# A31G12x_series register map
Vendor: ABOV Semiconductor Co., Ltd.; Series: A31G12x_series; File version: 1.0
CPU: CM0PLUS r0p1, little endian, no MPU, no FPU, VTOR, 2 interrupt priority bits
Registers are 32-bit, read-write, reset 0x0 unless marked. A register's access mark holds for its fields unless they carry their own. Offsets are from the block's base; [hi:lo] are bit positions; {n}, {i} and the like mark numbered series; 'fields as' and 'values as' point back to an identical list.

## CRC — CYCLIC REDUNDANCY CHECK AND CHECKSUM
Base 0x30001000
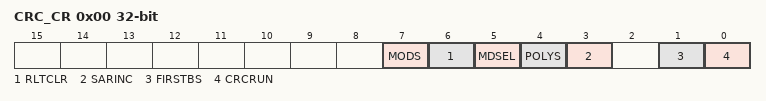
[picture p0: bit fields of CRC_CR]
0x00 CRC_CR — CRC/Checksum Control Register. Notes: 1. The CRCRLT register and the CRC/Checksum block should be initialized by writing "1b" to the RLTCLR bit before a new CRC/Checksum calculation. 2. The CRCRUN bit should be set to "1b" last time after setting appropriate values to the registers. 3. On the user mode, it will be calculated every writing data to the CRCIN register during CRCRUN==1. 4. On the user mode with SARINC==0, the block is finished by writing "0b" to the CRCRUN bit. 4. It is prohibited writing any data to the CRCIN register during CRCRUN==0. 5. The checksum is calculated by byte unit. Ex) On 0x34A7E991, CRCRLT = 0x34 + 0xA7 + 0xE9 + 0x91.
  [7] MODS — User/Auto Mode Selection bit
  [6] RLTCLR — CRC/Checksum Result Data Register (CRCRLT) Initialization bit
  [5] MDSEL — CRC/Checksum Selection bit
  [4] POLYS — Polynomial Selection bit (CRC only)
  [3] SARINC — CRC/Checksum Start Address Auto Increment Control bit (User mode only)
  [1] FIRSTBS — First Shifted-in Selection bit (CRC only)
  [0] CRCRUN — CRC/Checksum Start Control and Busy bit
0x04 CRC_IN — CRC/Checksum Input Data Register
0x08 CRC_RLT ro reset 0xFFFF (reset mask 0xFFFF) — CRC/Checksum Result Data Register
0x0C CRC_INIT (reset mask 0xFFFF) — CRC/Checksum Initial Data Register
0x10 CRC_SADR reset 0x10000000 (reset mask 0xFFFFFFFC) — CRC/Checksum Start Address Register. Note: The LSB-7bits of the start address should be "0x00" on the "Auto mode".
0x14 CRC_EADR reset 0x10007FFC (reset mask 0xFFFFFFFC) — CRC/Checksum End Address Register. Note: The LSB-7bits of the end address should be "0x7c" on the "Auto mode".

## INT — Interrupt
Base 0x40001000
0x04 INTC_PBTRIG (reset mask 0xFFF) — Port B Interrupt Trigger Selection Register
  [n] ITRIG{n} (n=2..11) — Pin {n} Interrupt Trigger Selection bit
  [?] ITRIG1 — Pin 1 Interrupt Trigger Selection bit
  [0] ITRIG0 — Pin 0 Interrupt Trigger Selection bit
0x08 INTC_PCTRIG (reset mask 0xF) — Port C Interrupt Trigger Selection Register
  [n] ITRIG{n} (n=2..7) — Pin {n} Interrupt Trigger Selection bit
  [?] ITRIG1 — Pin 1 Interrupt Trigger Selection bit
  [0] ITRIG0 — Pin 0 Interrupt Trigger Selection bit
0x10 INTC_PETRIG (reset mask 0xF) — Port E Interrupt Trigger Selection Register
  fields as INTC_PCTRIG
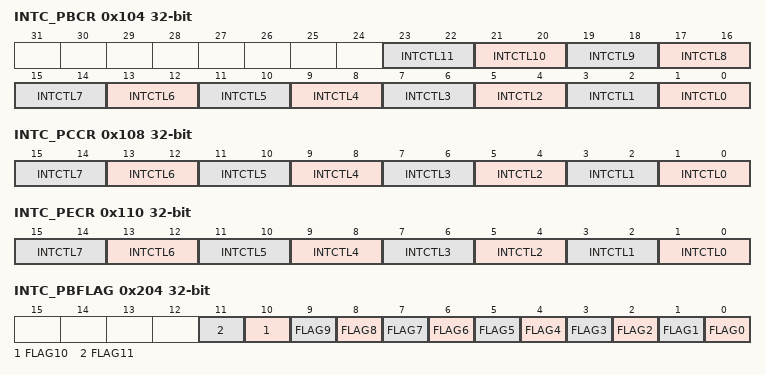
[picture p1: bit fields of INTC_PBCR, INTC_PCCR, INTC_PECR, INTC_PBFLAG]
0x104 INTC_PBCR — Port B Interrupt Control Register
  [2n+1:2n] INTCTL{n} (n=0..11) — Pin {n} Interrupt Control bits
0x108 INTC_PCCR (reset mask 0xFF) — Port C Interrupt Control Register
  [2n+1:2n] INTCTL{n} (n=0..7) — Pin {n} Interrupt Control bits
0x110 INTC_PECR (reset mask 0xFF) — Port E Interrupt Control Register
  [2n+1:2n] INTCTL{n} (n=0..7) — Pin {n} Interrupt Control bits
0x204 INTC_PBFLAG — Port B Interrupt Flag Register
  [n] FLAG{n} (n=0..11) — Pin {n} Interrupt Flag bit
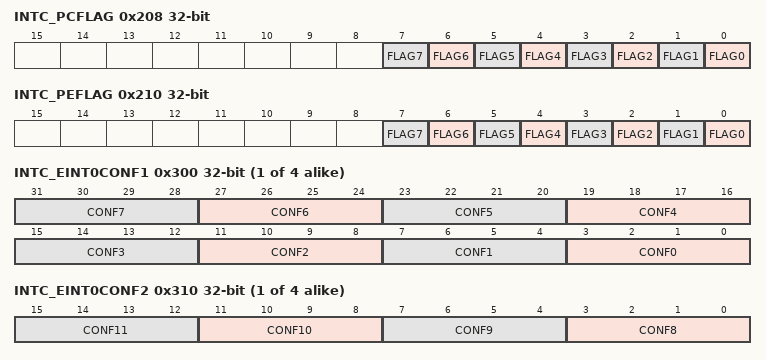
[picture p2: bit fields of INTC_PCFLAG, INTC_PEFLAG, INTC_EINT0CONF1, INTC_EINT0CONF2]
0x208 INTC_PCFLAG (reset mask 0xF) — Port C Interrupt Flag Register
  [n] FLAG{n} (n=0..7) — Pin {n} Interrupt Flag bit
0x210 INTC_PEFLAG (reset mask 0xF) — Port E Interrupt Flag Register
  [n] FLAG{n} (n=0..7) — Pin {n} Interrupt Flag bit
{0x300+4i} INTC_EINT{i}CONF1 (i=0..3) — External Interrupt {i} Configuration Register 1
  [4n+3:4n] CONF{n} (n=0..7) — Pin {n} Configuration bits for External Interrupt Group
{0x310+4i} INTC_EINT{i}CONF2 (i=0..3) — External Interrupt {i} Configuration Register 2
  [4n-29:4n-32] CONF{n} (n=8..11) — Pin {n} Configuration bits for External Interrupt Group
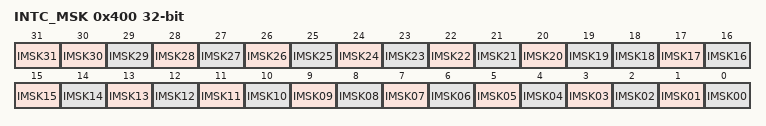
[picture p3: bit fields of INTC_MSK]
0x400 INTC_MSK — Interrupt Source Mask Register
  [31] IMSK31 — INT 31 Wake-up Source Mask bit from "Sleep"/"Deep Sleep" mode
    0=MASK; 1=UNMASK
  [n] IMSK{n} (n=19..30) — INT {n} Wake-up Source Mask bit from "Sleep"/"Deep Sleep" mode
  [n] IMSK{n:02} (n=0..18) — INT {n} Interrupt Source Mask bit from "Sleep"/"Deep Sleep" mode
